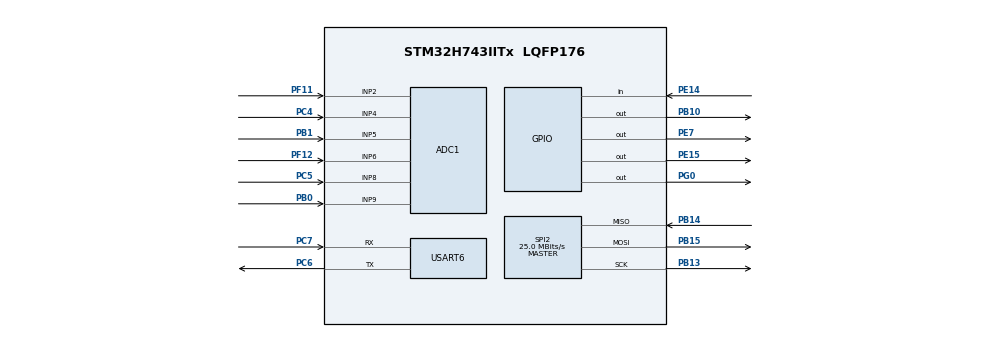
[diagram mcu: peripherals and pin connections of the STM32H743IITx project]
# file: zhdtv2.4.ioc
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ADC1.Channel-2\#ChannelRegularConversion=ADC_CHANNEL_2
ADC1.Channel-3\#ChannelRegularConversion=ADC_CHANNEL_8
ADC1.Channel-4\#ChannelRegularConversion=ADC_CHANNEL_5
ADC1.Channel-5\#ChannelRegularConversion=ADC_CHANNEL_4
ADC1.Channel-6\#ChannelRegularConversion=ADC_CHANNEL_9
ADC1.Channel-7\#ChannelRegularConversion=ADC_CHANNEL_6
ADC1.ClockPrescaler=ADC_CLOCK_ASYNC_DIV2
ADC1.ContinuousConvMode=DISABLE
ADC1.ConversionDataManagement=ADC_CONVERSIONDATA_DMA_CIRCULAR
ADC1.EOCSelection=ADC_EOC_SEQ_CONV
ADC1.EnableInjectedConversion=DISABLE
ADC1.ExternalTrigConv=ADC_EXTERNALTRIG_T8_TRGO
ADC1.NbrOfConversion=6
ADC1.NbrOfConversionFlag=1
ADC1.OffsetNumber-2\#ChannelRegularConversion=ADC_OFFSET_NONE
ADC1.OffsetNumber-3\#ChannelRegularConversion=ADC_OFFSET_NONE
ADC1.OffsetNumber-4\#ChannelRegularConversion=ADC_OFFSET_NONE
ADC1.OffsetNumber-5\#ChannelRegularConversion=ADC_OFFSET_NONE
ADC1.OffsetNumber-6\#ChannelRegularConversion=ADC_OFFSET_NONE
ADC1.OffsetNumber-7\#ChannelRegularConversion=ADC_OFFSET_NONE
ADC1.Overrun=ADC_OVR_DATA_OVERWRITTEN
ADC1.Rank-2\#ChannelRegularConversion=1
ADC1.Rank-3\#ChannelRegularConversion=2
ADC1.Rank-4\#ChannelRegularConversion=3
ADC1.Rank-5\#ChannelRegularConversion=4
ADC1.Rank-6\#ChannelRegularConversion=5
ADC1.Rank-7\#ChannelRegularConversion=6
ADC1.SamplingTime-2\#ChannelRegularConversion=ADC_SAMPLETIME_1CYCLE_5
ADC1.SamplingTime-3\#ChannelRegularConversion=ADC_SAMPLETIME_1CYCLE_5
ADC1.SamplingTime-4\#ChannelRegularConversion=ADC_SAMPLETIME_1CYCLE_5
ADC1.SamplingTime-5\#ChannelRegularConversion=ADC_SAMPLETIME_1CYCLE_5
ADC1.SamplingTime-6\#ChannelRegularConversion=ADC_SAMPLETIME_1CYCLE_5
ADC1.SamplingTime-7\#ChannelRegularConversion=ADC_SAMPLETIME_1CYCLE_5
ADC1.master=1
CORTEX_M7.AccessPermission-Cortex_Memory_Protection_Unit_Region0_Settings=MPU_REGION_FULL_ACCESS
CORTEX_M7.BaseAddress-Cortex_Memory_Protection_Unit_Region0_Settings=0x24000000
CORTEX_M7.CPU_DCache=Enabled
CORTEX_M7.CPU_ICache=Enabled
CORTEX_M7.DisableExec-Cortex_Memory_Protection_Unit_Region0_Settings=MPU_INSTRUCTION_ACCESS_ENABLE
CORTEX_M7.Enable-Cortex_Memory_Protection_Unit_Region0_Settings=MPU_REGION_ENABLE
CORTEX_M7.MPU_Control=MPU_PRIVILEGED_DEFAULT
CORTEX_M7.Size-Cortex_Memory_Protection_Unit_Region0_Settings=MPU_REGION_SIZE_512KB
Dma.ADC1.0.Direction=DMA_PERIPH_TO_MEMORY
Dma.ADC1.0.EventEnable=DISABLE
Dma.ADC1.0.FIFOMode=DMA_FIFOMODE_DISABLE
Dma.ADC1.0.Instance=DMA1_Stream0
Dma.ADC1.0.MemDataAlignment=DMA_MDATAALIGN_WORD
Dma.ADC1.0.MemInc=DMA_MINC_ENABLE
Dma.ADC1.0.Mode=DMA_CIRCULAR
Dma.ADC1.0.PeriphDataAlignment=DMA_PDATAALIGN_WORD
Dma.ADC1.0.PeriphInc=DMA_PINC_DISABLE
Dma.ADC1.0.Polarity=HAL_DMAMUX_REQ_GEN_RISING
Dma.ADC1.0.Priority=DMA_PRIORITY_VERY_HIGH
Dma.ADC1.0.RequestNumber=1
Dma.ADC1.0.SignalID=NONE
Dma.ADC1.0.SyncEnable=DISABLE
Dma.ADC1.0.SyncPolarity=HAL_DMAMUX_SYNC_NO_EVENT
Dma.ADC1.0.SyncRequestNumber=1
Dma.ADC1.0.SyncSignalID=NONE
Dma.Request0=ADC1
Mcu.Family=STM32H7
Mcu.Name=STM32H743IITx
Mcu.Package=LQFP176
NVIC.DMA1_Stream0_IRQn=true\:0\:0\:false\:false\:true\:false\:true
NVIC.PriorityGroup=NVIC_PRIORITYGROUP_4
NVIC.TIM2_IRQn=true\:0\:0\:false\:false\:true\:true\:true
NVIC.TIM8_UP_TIM13_IRQn=true\:0\:0\:false\:false\:true\:true\:true
PA13\ (JTMS/SWDIO).Mode=Trace_Asynchronous_SW
PA13\ (JTMS/SWDIO).Signal=DEBUG_JTMS-SWDIO
PA14\ (JTCK/SWCLK).Mode=Trace_Asynchronous_SW
PA14\ (JTCK/SWCLK).Signal=DEBUG_JTCK-SWCLK
PB0.Signal=ADCx_INP9
PB1.Signal=ADCx_INP5
PB10.Signal=GPIO_Output
PB13.Mode=Full_Duplex_Master
PB13.Signal=SPI2_SCK
PB14.Mode=Full_Duplex_Master
PB14.Signal=SPI2_MISO
PB15.Mode=Full_Duplex_Master
PB15.Signal=SPI2_MOSI
PB3\ (JTDO/TRACESWO).Mode=Trace_Asynchronous_SW
PB3\ (JTDO/TRACESWO).Signal=DEBUG_JTDO-SWO
PC4.Signal=ADCx_INP4
PC5.Signal=ADCx_INP8
PC6.Mode=Asynchronous
PC6.Signal=USART6_TX
PC7.Mode=Asynchronous
PC7.Signal=USART6_RX
PE14.Signal=GPIO_Input
PE15.Signal=GPIO_Output
PE7.GPIO_ModeDefaultOutputPP=GPIO_MODE_OUTPUT_PP
PE7.GPIO_PuPd=GPIO_NOPULL
PE7.GPIO_Speed=GPIO_SPEED_FREQ_LOW
PE7.PinState=GPIO_PIN_RESET
PE7.Signal=GPIO_Output
PF11.Mode=IN2-Single-Ended
PF11.Signal=ADC1_INP2
PF12.Mode=IN6-Single-Ended
PF12.Signal=ADC1_INP6
PG0.GPIO_ModeDefaultOutputPP=GPIO_MODE_OUTPUT_PP
PG0.GPIO_PuPd=GPIO_NOPULL
PG0.GPIO_Speed=GPIO_SPEED_FREQ_LOW
PG0.PinState=GPIO_PIN_RESET
PG0.Signal=GPIO_Output
PH0-OSC_IN\ (PH0).Mode=HSE-External-Oscillator
PH0-OSC_IN\ (PH0).Signal=RCC_OSC_IN
PH1-OSC_OUT\ (PH1).Mode=HSE-External-Oscillator
PH1-OSC_OUT\ (PH1).Signal=RCC_OSC_OUT
ProjectManager.HeapSize=0x200
ProjectManager.StackSize=0x400
ProjectManager.TargetToolchain=MDK-ARM V5
RCC.ADCCLockSelection=RCC_ADCCLKSOURCE_CLKP
RCC.ADCFreq_Value=64000000
RCC.APB1Freq_Value=100000000
RCC.APB2Freq_Value=100000000
RCC.APB3Freq_Value=100000000
RCC.APB4Freq_Value=100000000
RCC.CortexFreq_Value=400000000
RCC.D1PPRE=RCC_APB3_DIV2
RCC.D2PPRE1=RCC_APB1_DIV2
RCC.D2PPRE2=RCC_APB2_DIV2
RCC.D3PPRE=RCC_APB4_DIV2
RCC.DIVM1=2
RCC.DIVM2=2
RCC.DIVN1=64
RCC.DIVN2=12
RCC.DIVP2=1
RCC.HCLKFreq_Value=200000000
RCC.HPRE=RCC_HCLK_DIV2
RCC.PLL2FRACN=0
RCC.PLL3FRACN=0
RCC.PLLFRACN=0
RCC.PLLSourceVirtual=RCC_PLLSOURCE_HSE
RCC.SYSCLKFreq_VALUE=400000000
RCC.SYSCLKSource=RCC_SYSCLKSOURCE_PLLCLK
RCC.USBFreq_Value=400000000
SH.ADCx_INP4.0=ADC1_INP4,IN4-Single-Ended
SH.ADCx_INP5.0=ADC1_INP5,IN5-Single-Ended
SH.ADCx_INP8.0=ADC1_INP8,IN8-Single-Ended
SH.ADCx_INP9.0=ADC1_INP9,IN9-Single-Ended
SPI2.BaudRatePrescaler=SPI_BAUDRATEPRESCALER_16
SPI2.CLKPhase=SPI_PHASE_2EDGE
SPI2.CLKPolarity=SPI_POLARITY_HIGH
SPI2.CRCCalculation=SPI_CRCCALCULATION_ENABLE
SPI2.CRCLength=SPI_CRC_LENGTH_8BIT
SPI2.CalculateBaudRate=25.0 MBits/s
SPI2.DataSize=SPI_DATASIZE_8BIT
SPI2.Direction=SPI_DIRECTION_2LINES
SPI2.MasterKeepIOState=SPI_MASTER_KEEP_IO_STATE_DISABLE
SPI2.Mode=SPI_MODE_MASTER
SPI2.NSSPMode=SPI_NSS_PULSE_DISABLE
SPI2.VirtualType=VM_MASTER
TIM2.Period=1000
TIM2.Prescaler=200
TIM8.Period=5000
TIM8.Prescaler=200
TIM8.TIM_MasterOutputTrigger=TIM_TRGO_UPDATE
TIM8.TIM_MasterSlaveMode=TIM_MASTERSLAVEMODE_ENABLE
USART6.VirtualMode-Asynchronous=VM_ASYNC
VP_TIM2_VS_ClockSourceINT.Mode=Internal
VP_TIM8_VS_ClockSourceINT.Mode=Internal
board=custom

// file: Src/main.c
/* USER CODE BEGIN Header */
/**
  ******************************************************************************
  * @file           : main.c
  * @brief          : Main program body
  ******************************************************************************
  * @attention
  *
  * <h2><center>&copy; Copyright (c) 2019 STMicroelectronics.
  * All rights reserved.</center></h2>
  *
  * This software component is licensed by ST under BSD 3-Clause license,
  * the "License"; You may not use this file except in compliance with the
  * License. You may obtain a copy of the License at:
  *                        opensource.org/licenses/BSD-3-Clause
  *
  ******************************************************************************
  */
/* USER CODE END Header */

#include "main.h"

/* USER CODE BEGIN Includes */
#include "stdio.h"
#include "string.h"
#include "w5500.h"
#include "socket.h"
#include "dhcp.h"
//#include "delay.h"
#include "w5500_config.h"
/* USER CODE END Includes */

/* USER CODE BEGIN PD */
#ifdef __GNUC__
  /* With GCC/RAISONANCE, small printf (option LD Linker->Libraries->Small printf
     set to 'Yes') calls __io_putchar() */
  #define PUTCHAR_PROTOTYPE int __io_putchar(int ch)
#else
  #define PUTCHAR_PROTOTYPE int fputc(int ch, FILE *f)
#endif /* __GNUC__ */

/* USER CODE END PD */

/* USER CODE BEGIN PM */
uint32_t ADC_DATA[ADC_CONVERTED_DATA_BUFFER_SIZE] __attribute__((section(".ARM.__at_0x24000000")));
//uint32_t ADC_DATA[ADC_CONVERTED_DATA_BUFFER_SIZE] ;
uint32_t ad1,ad2;
uint16_t i;
uint8_t reset_cmd = 0;
/* USER CODE END PM */

ADC_HandleTypeDef hadc1;
DMA_HandleTypeDef hdma_adc1;

SPI_HandleTypeDef hspi2;

TIM_HandleTypeDef htim2;
TIM_HandleTypeDef htim8;

UART_HandleTypeDef huart6;

/* USER CODE BEGIN PV */
PUTCHAR_PROTOTYPE
{
  /* Place your implementation of fputc here */
  /* e.g. write a character to the EVAL_COM1 and Loop until the end of transmission */
  HAL_UART_Transmit(&huart6, (uint8_t *)&ch, 1, 0xFFFF);

  return ch;
}
/* USER CODE END PV */

void SystemClock_Config(void);
static void MPU_Config(void);
static void MX_GPIO_Init(void);
static void MX_DMA_Init(void);
static void MX_USART6_UART_Init(void);
static void MX_ADC1_Init(void);
static void MX_SPI2_Init(void);
static void MX_TIM2_Init(void);
static void MX_TIM8_Init(void);
/* USER CODE BEGIN PFP */

void software(void);
/* USER CODE END PFP */

int main(void)
{

  /* MPU Configuration--------------------------------------------------------*/
  MPU_Config();

  /* Enable I-Cache---------------------------------------------------------*/
  SCB_EnableICache();

  /* Enable D-Cache---------------------------------------------------------*/
  SCB_EnableDCache();

  /* MCU Configuration--------------------------------------------------------*/

  /* Reset of all peripherals, Initializes the Flash interface and the Systick. */
  HAL_Init();

  /* Configure the system clock */
  SystemClock_Config();

  /* Initialize all configured peripherals */
  MX_GPIO_Init();
  MX_DMA_Init();
  MX_USART6_UART_Init();
  MX_ADC1_Init();
  MX_SPI2_Init();
  MX_TIM2_Init();
  MX_TIM8_Init();
  /* USER CODE BEGIN 2 */
	GetLockCode();
	Reset_W5500();
	w5500_check();
	set_w5500_mac();
	sysinit(txsize, rxsize);
	printf("W5500 Init Complete!\r\n");
//	set_w5500_ip();
	//setkeepalive(0);
	if (HAL_ADC_Start_DMA(&hadc1, (uint32_t *)ADC_DATA, ADC_CONVERTED_DATA_BUFFER_SIZE) != HAL_OK)
	{
		Error_Handler();
	}
	HAL_TIM_Base_Start_IT(&htim2);
	HAL_TIM_Base_Start_IT(&htim8);
	LED0_ON;
	LED1_OFF;
	//printf("cumulative_add = %d.\r\n",sizeof(uint8_t));
  /* USER CODE END 2 */

  /* Infinite loop */
  while (1)
  {

    /* USER CODE BEGIN 3 */
		w5500_check();
		if(dhcp_ok != 1)
		{
		//	HAL_Delay(1000);
			auto_dhcp();
		//	set_w5500_ip();
			HAL_Delay(1000);
		}
		if(dhcp_ok == 1)
		{

			do_tcp_client();
			/*
				 头							id							数据长度（俩个字节）							序号（一个字节）								数据
			0xff	0xff			四个字节					实际发送数据长度									验证丢包累积+									  xx  xx  yy yy xx xx yy yy  xx xx yy  yy
			*/
			if((socket_flag == 0)&&(u8len - 9 >= 1200))//&&(sev_time_ok == 1))
			{
					sev_time_ok = 0;
					sev_data = 0;
					Cache_buffer[0] = 0xFF;
					Cache_buffer[1] = 0xFF;
					//Cache_buffer[2] = cumulative_add >> 24;
					//Cache_buffer[3] = cumulative_add >> 16;
					//Cache_buffer[4] = cumulative_add >> 8;
					//Cache_buffer[5] = cumulative_add & 0x00000000000000ff;

					Cache_buffer[2] = id_name[0];
					Cache_buffer[3] = id_name[1];
					Cache_buffer[4] = id_name[2];
					Cache_buffer[5] = id_name[3];
					Cache_buffer[6] = (u8len-8) >> 8;
					Cache_buffer[7] = (u8len-8) & 0x00ff;

				Cache_buffer[8] = ++sev_crc;
					send(0,Cache_buffer,u8len);
					//printf("Total len = %d\r\n",u8len);
					u8len = 9;
					memset(Cache_buffer,0,sizeof(Cache_buffer));
			}
			if((sev_data == 1)&&(socket_flag == 0))
			{
				sev_data = 0;
				u32_to_u8(ADC_DATA,w5500_buffer,sevbuffer_len);
				memcpy(&Cache_buffer[u8len],w5500_buffer,sevbuffer_len*2);
				u8len += sevbuffer_len*2;
			}
//			if(cumulative_add%2000 == 0)
//			{
//				LED0_ON;
//				LED1_OFF;
//			}
		}
			if(w5500_connect_error > 10000)
			{
//				dhcp_ok = 0;
				reset_cmd++;
				LED0_OFF;
				LED1_ON;
				w5500_connect_error = 0;
				printf("w5500 connect error.try reconnecting.\r\n");
				Reset_W5500();
				HAL_Delay(100);
				set_w5500_mac();
				sysinit(txsize, rxsize);
				setkeepalive(0);
			}
			if(reset_cmd >= 2)
			{
				software();
			}

	}
  /* USER CODE END 3 */
}

void SystemClock_Config(void)
{
  RCC_OscInitTypeDef RCC_OscInitStruct = {0};
  RCC_ClkInitTypeDef RCC_ClkInitStruct = {0};
  RCC_PeriphCLKInitTypeDef PeriphClkInitStruct = {0};

  /** Supply configuration update enable
  */
  HAL_PWREx_ConfigSupply(PWR_LDO_SUPPLY);
  /** Configure the main internal regulator output voltage
  */
  __HAL_PWR_VOLTAGESCALING_CONFIG(PWR_REGULATOR_VOLTAGE_SCALE1);

  while(!__HAL_PWR_GET_FLAG(PWR_FLAG_VOSRDY)) {}
  /** Initializes the CPU, AHB and APB busses clocks
  */
  RCC_OscInitStruct.OscillatorType = RCC_OSCILLATORTYPE_HSI|RCC_OSCILLATORTYPE_HSE;
  RCC_OscInitStruct.HSEState = RCC_HSE_ON;
  RCC_OscInitStruct.HSIState = RCC_HSI_DIV1;
  RCC_OscInitStruct.HSICalibrationValue = RCC_HSICALIBRATION_DEFAULT;
  RCC_OscInitStruct.PLL.PLLState = RCC_PLL_ON;
  RCC_OscInitStruct.PLL.PLLSource = RCC_PLLSOURCE_HSE;
  RCC_OscInitStruct.PLL.PLLM = 2;
  RCC_OscInitStruct.PLL.PLLN = 64;
  RCC_OscInitStruct.PLL.PLLP = 2;
  RCC_OscInitStruct.PLL.PLLQ = 2;
  RCC_OscInitStruct.PLL.PLLR = 2;
  RCC_OscInitStruct.PLL.PLLRGE = RCC_PLL1VCIRANGE_3;
  RCC_OscInitStruct.PLL.PLLVCOSEL = RCC_PLL1VCOWIDE;
  RCC_OscInitStruct.PLL.PLLFRACN = 0;
  if (HAL_RCC_OscConfig(&RCC_OscInitStruct) != HAL_OK)
  {
    Error_Handler();
  }
  /** Initializes the CPU, AHB and APB busses clocks
  */
  RCC_ClkInitStruct.ClockType = RCC_CLOCKTYPE_HCLK|RCC_CLOCKTYPE_SYSCLK
                              |RCC_CLOCKTYPE_PCLK1|RCC_CLOCKTYPE_PCLK2
                              |RCC_CLOCKTYPE_D3PCLK1|RCC_CLOCKTYPE_D1PCLK1;
  RCC_ClkInitStruct.SYSCLKSource = RCC_SYSCLKSOURCE_PLLCLK;
  RCC_ClkInitStruct.SYSCLKDivider = RCC_SYSCLK_DIV1;
  RCC_ClkInitStruct.AHBCLKDivider = RCC_HCLK_DIV2;
  RCC_ClkInitStruct.APB3CLKDivider = RCC_APB3_DIV2;
  RCC_ClkInitStruct.APB1CLKDivider = RCC_APB1_DIV2;
  RCC_ClkInitStruct.APB2CLKDivider = RCC_APB2_DIV2;
  RCC_ClkInitStruct.APB4CLKDivider = RCC_APB4_DIV2;

  if (HAL_RCC_ClockConfig(&RCC_ClkInitStruct, FLASH_LATENCY_2) != HAL_OK)
  {
    Error_Handler();
  }
  PeriphClkInitStruct.PeriphClockSelection = RCC_PERIPHCLK_USART6|RCC_PERIPHCLK_SPI2
                              |RCC_PERIPHCLK_ADC|RCC_PERIPHCLK_CKPER;
  PeriphClkInitStruct.CkperClockSelection = RCC_CLKPSOURCE_HSI;
  PeriphClkInitStruct.Spi123ClockSelection = RCC_SPI123CLKSOURCE_PLL;
  PeriphClkInitStruct.Usart16ClockSelection = RCC_USART16CLKSOURCE_D2PCLK2;
  PeriphClkInitStruct.AdcClockSelection = RCC_ADCCLKSOURCE_CLKP;
  if (HAL_RCCEx_PeriphCLKConfig(&PeriphClkInitStruct) != HAL_OK)
  {
    Error_Handler();
  }
}

static void MX_ADC1_Init(void)
{

  ADC_MultiModeTypeDef multimode = {0};
  ADC_ChannelConfTypeDef sConfig = {0};

  /** Common config
  */
  hadc1.Instance = ADC1;
  hadc1.Init.ClockPrescaler = ADC_CLOCK_ASYNC_DIV2;
  hadc1.Init.Resolution = ADC_RESOLUTION_16B;
  hadc1.Init.ScanConvMode = ADC_SCAN_ENABLE;
  hadc1.Init.EOCSelection = ADC_EOC_SEQ_CONV;
  hadc1.Init.LowPowerAutoWait = DISABLE;
  hadc1.Init.ContinuousConvMode = DISABLE;
  hadc1.Init.NbrOfConversion = 6;
  hadc1.Init.DiscontinuousConvMode = DISABLE;
  hadc1.Init.ExternalTrigConv = ADC_EXTERNALTRIG_T8_TRGO;
  hadc1.Init.ExternalTrigConvEdge = ADC_EXTERNALTRIGCONVEDGE_RISING;
  hadc1.Init.ConversionDataManagement = ADC_CONVERSIONDATA_DMA_CIRCULAR;
  hadc1.Init.Overrun = ADC_OVR_DATA_OVERWRITTEN;
  hadc1.Init.LeftBitShift = ADC_LEFTBITSHIFT_NONE;
  hadc1.Init.OversamplingMode = DISABLE;
  if (HAL_ADC_Init(&hadc1) != HAL_OK)
  {
    Error_Handler();
  }
  /** Configure the ADC multi-mode
  */
  multimode.Mode = ADC_MODE_INDEPENDENT;
  if (HAL_ADCEx_MultiModeConfigChannel(&hadc1, &multimode) != HAL_OK)
  {
    Error_Handler();
  }
  /** Configure Regular Channel
  */
  sConfig.Channel = ADC_CHANNEL_2;
  sConfig.Rank = ADC_REGULAR_RANK_1;
  sConfig.SamplingTime = ADC_SAMPLETIME_1CYCLE_5;
  sConfig.SingleDiff = ADC_SINGLE_ENDED;
  sConfig.OffsetNumber = ADC_OFFSET_NONE;
  sConfig.Offset = 0;
  if (HAL_ADC_ConfigChannel(&hadc1, &sConfig) != HAL_OK)
  {
    Error_Handler();
  }
  /** Configure Regular Channel
  */
  sConfig.Channel = ADC_CHANNEL_8;
  sConfig.Rank = ADC_REGULAR_RANK_2;
  if (HAL_ADC_ConfigChannel(&hadc1, &sConfig) != HAL_OK)
  {
    Error_Handler();
  }
  /** Configure Regular Channel
  */
  sConfig.Channel = ADC_CHANNEL_5;
  sConfig.Rank = ADC_REGULAR_RANK_3;
  if (HAL_ADC_ConfigChannel(&hadc1, &sConfig) != HAL_OK)
  {
    Error_Handler();
  }
  /** Configure Regular Channel
  */
  sConfig.Channel = ADC_CHANNEL_4;
  sConfig.Rank = ADC_REGULAR_RANK_4;
  if (HAL_ADC_ConfigChannel(&hadc1, &sConfig) != HAL_OK)
  {
    Error_Handler();
  }
  /** Configure Regular Channel
  */
  sConfig.Channel = ADC_CHANNEL_9;
  sConfig.Rank = ADC_REGULAR_RANK_5;
  if (HAL_ADC_ConfigChannel(&hadc1, &sConfig) != HAL_OK)
  {
    Error_Handler();
  }
  /** Configure Regular Channel
  */
  sConfig.Channel = ADC_CHANNEL_6;
  sConfig.Rank = ADC_REGULAR_RANK_6;
  if (HAL_ADC_ConfigChannel(&hadc1, &sConfig) != HAL_OK)
  {
    Error_Handler();
  }

}

static void MX_SPI2_Init(void)
{

  /* SPI2 parameter configuration*/
  hspi2.Instance = SPI2;
  hspi2.Init.Mode = SPI_MODE_MASTER;
  hspi2.Init.Direction = SPI_DIRECTION_2LINES;
  hspi2.Init.DataSize = SPI_DATASIZE_8BIT;
  hspi2.Init.CLKPolarity = SPI_POLARITY_HIGH;
  hspi2.Init.CLKPhase = SPI_PHASE_2EDGE;
  hspi2.Init.NSS = SPI_NSS_SOFT;
  hspi2.Init.BaudRatePrescaler = SPI_BAUDRATEPRESCALER_16;
  hspi2.Init.FirstBit = SPI_FIRSTBIT_MSB;
  hspi2.Init.TIMode = SPI_TIMODE_DISABLE;
  hspi2.Init.CRCCalculation = SPI_CRCCALCULATION_ENABLE;
  hspi2.Init.CRCPolynomial = 0x107;
  hspi2.Init.CRCLength = SPI_CRC_LENGTH_8BIT;
  hspi2.Init.NSSPMode = SPI_NSS_PULSE_DISABLE;
  hspi2.Init.NSSPolarity = SPI_NSS_POLARITY_LOW;
  hspi2.Init.FifoThreshold = SPI_FIFO_THRESHOLD_01DATA;
  hspi2.Init.TxCRCInitializationPattern = SPI_CRC_INITIALIZATION_ALL_ZERO_PATTERN;
  hspi2.Init.RxCRCInitializationPattern = SPI_CRC_INITIALIZATION_ALL_ZERO_PATTERN;
  hspi2.Init.MasterSSIdleness = SPI_MASTER_SS_IDLENESS_00CYCLE;
  hspi2.Init.MasterInterDataIdleness = SPI_MASTER_INTERDATA_IDLENESS_00CYCLE;
  hspi2.Init.MasterReceiverAutoSusp = SPI_MASTER_RX_AUTOSUSP_DISABLE;
  hspi2.Init.MasterKeepIOState = SPI_MASTER_KEEP_IO_STATE_DISABLE;
  hspi2.Init.IOSwap = SPI_IO_SWAP_DISABLE;
  if (HAL_SPI_Init(&hspi2) != HAL_OK)
  {
    Error_Handler();
  }

}

static void MX_TIM2_Init(void)
{

  TIM_ClockConfigTypeDef sClockSourceConfig = {0};
  TIM_MasterConfigTypeDef sMasterConfig = {0};

  htim2.Instance = TIM2;
  htim2.Init.Prescaler = 200;
  htim2.Init.CounterMode = TIM_COUNTERMODE_UP;
  htim2.Init.Period = 1000;
  htim2.Init.ClockDivision = TIM_CLOCKDIVISION_DIV1;
  htim2.Init.AutoReloadPreload = TIM_AUTORELOAD_PRELOAD_DISABLE;
  if (HAL_TIM_Base_Init(&htim2) != HAL_OK)
  {
    Error_Handler();
  }
  sClockSourceConfig.ClockSource = TIM_CLOCKSOURCE_INTERNAL;
  if (HAL_TIM_ConfigClockSource(&htim2, &sClockSourceConfig) != HAL_OK)
  {
    Error_Handler();
  }
  sMasterConfig.MasterOutputTrigger = TIM_TRGO_RESET;
  sMasterConfig.MasterSlaveMode = TIM_MASTERSLAVEMODE_DISABLE;
  if (HAL_TIMEx_MasterConfigSynchronization(&htim2, &sMasterConfig) != HAL_OK)
  {
    Error_Handler();
  }

}

static void MX_TIM8_Init(void)
{

  TIM_ClockConfigTypeDef sClockSourceConfig = {0};
  TIM_MasterConfigTypeDef sMasterConfig = {0};

  htim8.Instance = TIM8;
  htim8.Init.Prescaler = 200-1;
  htim8.Init.CounterMode = TIM_COUNTERMODE_UP;
  htim8.Init.Period = 200-1;
  htim8.Init.ClockDivision = TIM_CLOCKDIVISION_DIV1;
  htim8.Init.RepetitionCounter = 0;
  htim8.Init.AutoReloadPreload = TIM_AUTORELOAD_PRELOAD_DISABLE;
  if (HAL_TIM_Base_Init(&htim8) != HAL_OK)
  {
    Error_Handler();
  }
  sClockSourceConfig.ClockSource = TIM_CLOCKSOURCE_INTERNAL;
  if (HAL_TIM_ConfigClockSource(&htim8, &sClockSourceConfig) != HAL_OK)
  {
    Error_Handler();
  }
  sMasterConfig.MasterOutputTrigger = TIM_TRGO_UPDATE;
  sMasterConfig.MasterOutputTrigger2 = TIM_TRGO2_RESET;
  sMasterConfig.MasterSlaveMode = TIM_MASTERSLAVEMODE_ENABLE;
  if (HAL_TIMEx_MasterConfigSynchronization(&htim8, &sMasterConfig) != HAL_OK)
  {
    Error_Handler();
  }

}

static void MX_USART6_UART_Init(void)
{

  huart6.Instance = USART6;
  huart6.Init.BaudRate = 115200;
  huart6.Init.WordLength = UART_WORDLENGTH_8B;
  huart6.Init.StopBits = UART_STOPBITS_1;
  huart6.Init.Parity = UART_PARITY_NONE;
  huart6.Init.Mode = UART_MODE_TX_RX;
  huart6.Init.HwFlowCtl = UART_HWCONTROL_NONE;
  huart6.Init.OverSampling = UART_OVERSAMPLING_16;
  huart6.Init.OneBitSampling = UART_ONE_BIT_SAMPLE_DISABLE;
  huart6.Init.ClockPrescaler = UART_PRESCALER_DIV1;
  huart6.AdvancedInit.AdvFeatureInit = UART_ADVFEATURE_NO_INIT;
  if (HAL_UART_Init(&huart6) != HAL_OK)
  {
    Error_Handler();
  }
  if (HAL_UARTEx_SetTxFifoThreshold(&huart6, UART_TXFIFO_THRESHOLD_1_8) != HAL_OK)
  {
    Error_Handler();
  }
  if (HAL_UARTEx_SetRxFifoThreshold(&huart6, UART_RXFIFO_THRESHOLD_1_8) != HAL_OK)
  {
    Error_Handler();
  }
  if (HAL_UARTEx_DisableFifoMode(&huart6) != HAL_OK)
  {
    Error_Handler();
  }

}

static void MX_DMA_Init(void)
{

  /* DMA controller clock enable */
  __HAL_RCC_DMA1_CLK_ENABLE();

  /* DMA interrupt init */
  /* DMA1_Stream0_IRQn interrupt configuration */
  HAL_NVIC_SetPriority(DMA1_Stream0_IRQn, 0, 0);
  HAL_NVIC_EnableIRQ(DMA1_Stream0_IRQn);

}

static void MX_GPIO_Init(void)
{
  GPIO_InitTypeDef GPIO_InitStruct = {0};

  /* GPIO Ports Clock Enable */
  __HAL_RCC_GPIOH_CLK_ENABLE();
  __HAL_RCC_GPIOC_CLK_ENABLE();
  __HAL_RCC_GPIOB_CLK_ENABLE();
  __HAL_RCC_GPIOF_CLK_ENABLE();
  __HAL_RCC_GPIOG_CLK_ENABLE();
  __HAL_RCC_GPIOE_CLK_ENABLE();
  __HAL_RCC_GPIOA_CLK_ENABLE();

  /*Configure GPIO pin Output Level */
  HAL_GPIO_WritePin(GPIOF, GPIO_PIN_15, GPIO_PIN_SET);

  /*Configure GPIO pin Output Level */
  HAL_GPIO_WritePin(GPIOE, GPIO_PIN_7|GPIO_PIN_15, GPIO_PIN_RESET);

  /*Configure GPIO pin Output Level */
  HAL_GPIO_WritePin(GPIOB, GPIO_PIN_10, GPIO_PIN_RESET);

  /*Configure GPIO pin : PG0 */
  GPIO_InitStruct.Pin = GPIO_PIN_15;
  GPIO_InitStruct.Mode = GPIO_MODE_OUTPUT_PP;
  GPIO_InitStruct.Pull = GPIO_NOPULL;
  GPIO_InitStruct.Speed = GPIO_SPEED_FREQ_LOW;
  HAL_GPIO_Init(GPIOF, &GPIO_InitStruct);

  /*Configure GPIO pins : PE7 PE15 */
  GPIO_InitStruct.Pin = GPIO_PIN_7|GPIO_PIN_15;
  GPIO_InitStruct.Mode = GPIO_MODE_OUTPUT_PP;
  GPIO_InitStruct.Pull = GPIO_NOPULL;
  GPIO_InitStruct.Speed = GPIO_SPEED_FREQ_LOW;
  HAL_GPIO_Init(GPIOE, &GPIO_InitStruct);

  /*Configure GPIO pin : PE14 */
  GPIO_InitStruct.Pin = GPIO_PIN_14;
  GPIO_InitStruct.Mode = GPIO_MODE_INPUT;
  GPIO_InitStruct.Pull = GPIO_NOPULL;
  HAL_GPIO_Init(GPIOE, &GPIO_InitStruct);

  /*Configure GPIO pin : PB10 */
  GPIO_InitStruct.Pin = GPIO_PIN_10;
  GPIO_InitStruct.Mode = GPIO_MODE_OUTPUT_PP;
  GPIO_InitStruct.Pull = GPIO_NOPULL;
  GPIO_InitStruct.Speed = GPIO_SPEED_FREQ_LOW;
  HAL_GPIO_Init(GPIOB, &GPIO_InitStruct);

}

/* USER CODE BEGIN 4 */
void HAL_TIM_PeriodElapsedCallback(TIM_HandleTypeDef *htim)
{
  if(htim->Instance == TIM2)
  {
			w5500_connect_error++;
			cumulative_add++;
			if(cumulative_add%20 == 0)
			{
				sev_time_ok = 1;
			}
  }
}
void HAL_ADC_ConvHalfCpltCallback(ADC_HandleTypeDef* hadc)
{
  /* Invalidate Data Cache to get the updated content of the SRAM on the first half of the ADC converted data buffer: 32 bytes */
  SCB_InvalidateDCache_by_Addr((uint32_t *) &ADC_DATA[0], ADC_CONVERTED_DATA_BUFFER_SIZE);
}
void HAL_ADC_ConvCpltCallback(ADC_HandleTypeDef* hadc)
{
   /* Invalidate Data Cache to get the updated content of the SRAM on the second half of the ADC converted data buffer: 32 bytes */
  SCB_InvalidateDCache_by_Addr((uint32_t *) &ADC_DATA[ADC_CONVERTED_DATA_BUFFER_SIZE/2], ADC_CONVERTED_DATA_BUFFER_SIZE);
	sev_data = 1;
}
void software(void)
{
	__set_FAULTMASK(1);
	NVIC_SystemReset();
}

/* USER CODE END 4 */

/* MPU Configuration */

void MPU_Config(void)
{
  MPU_Region_InitTypeDef MPU_InitStruct = {0};

  /* Disables the MPU */
  HAL_MPU_Disable();
  /** Initializes and configures the Region and the memory to be protected
  */
  MPU_InitStruct.Enable = MPU_REGION_ENABLE;
  MPU_InitStruct.Number = MPU_REGION_NUMBER0;
  MPU_InitStruct.BaseAddress = 0x24000000;
  MPU_InitStruct.Size = MPU_REGION_SIZE_512KB;
  MPU_InitStruct.SubRegionDisable = 0x0;
  MPU_InitStruct.TypeExtField = MPU_TEX_LEVEL0;
  MPU_InitStruct.AccessPermission = MPU_REGION_FULL_ACCESS;
  MPU_InitStruct.DisableExec = MPU_INSTRUCTION_ACCESS_ENABLE;
  MPU_InitStruct.IsShareable = MPU_ACCESS_NOT_SHAREABLE;
  MPU_InitStruct.IsCacheable = MPU_ACCESS_NOT_CACHEABLE;
  MPU_InitStruct.IsBufferable = MPU_ACCESS_NOT_BUFFERABLE;

  HAL_MPU_ConfigRegion(&MPU_InitStruct);
  /* Enables the MPU */
  HAL_MPU_Enable(MPU_PRIVILEGED_DEFAULT);

}

void Error_Handler(void)
{
}

/************************ (C) COPYRIGHT STMicroelectronics *****END OF FILE****/
